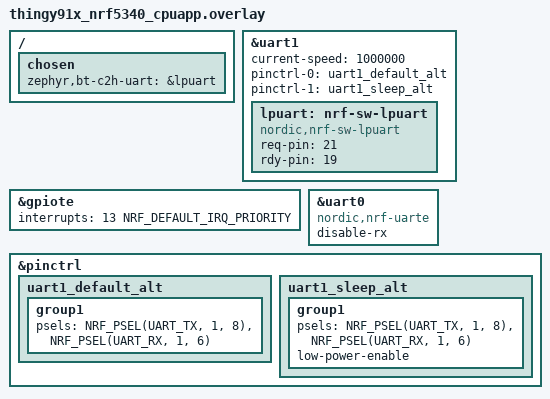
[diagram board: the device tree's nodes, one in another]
/* SPDX-License-Identifier: LicenseRef-Nordic-5-Clause */

/ {
	chosen {
		zephyr,bt-c2h-uart=&lpuart;
	};
};

&uart1 {
	current-speed = <1000000>;
	status = "okay";

	pinctrl-0 = <&uart1_default_alt>;
	pinctrl-1 = <&uart1_sleep_alt>;
	pinctrl-names = "default", "sleep";
	lpuart: nrf-sw-lpuart {
		compatible = "nordic,nrf-sw-lpuart";
		status = "okay";
		req-pin = <21>;
		rdy-pin = <19>;
	};
};

&gpiote {
	interrupts = <13 NRF_DEFAULT_IRQ_PRIORITY>;
};

/* Disabling uart rx pin to get low power */
&uart0 {
	compatible = "nordic,nrf-uarte";
	disable-rx;
};

&pinctrl {
	uart1_default_alt: uart1_default_alt {
		group1 {
			psels = <NRF_PSEL(UART_TX, 1, 8)>,
				<NRF_PSEL(UART_RX, 1, 6)>;
		};
	};

	uart1_sleep_alt: uart1_sleep_alt {
		group1 {
			psels = <NRF_PSEL(UART_TX, 1, 8)>,
				<NRF_PSEL(UART_RX, 1, 6)>;
			low-power-enable;
		};
	};
};
